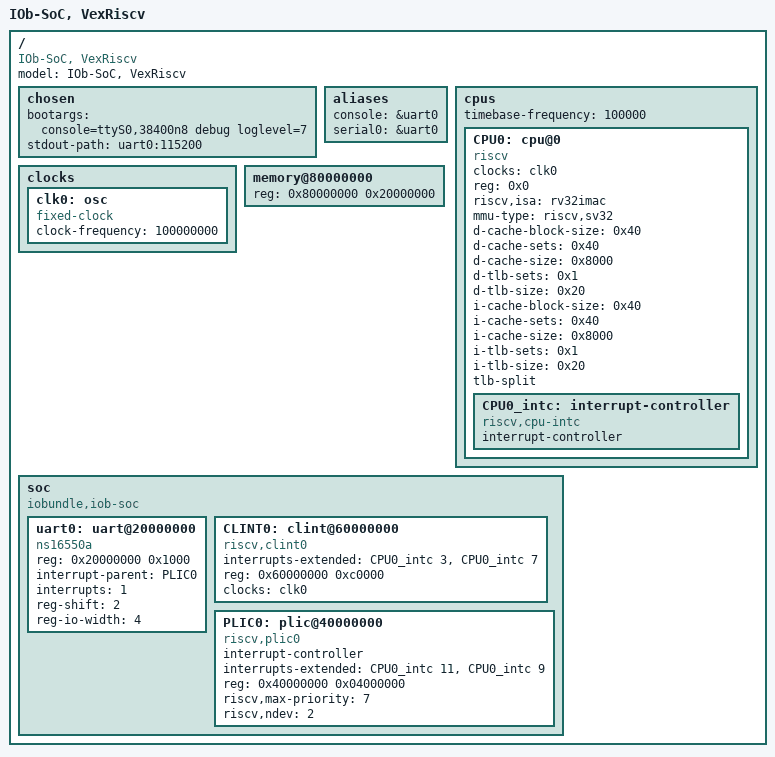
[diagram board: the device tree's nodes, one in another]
// SPDX-License-Identifier: (GPL-2.0 OR MIT)
/* Copyright (c) 2023 Pedro Antunes <pedronmantunes@gmail.com> */

/dts-v1/;

/ {
	#address-cells = <1>;
	#size-cells = <1>;
	model = "IOb-SoC, VexRiscv";
	compatible = "IOb-SoC, VexRiscv";

	chosen {
		bootargs = "console=ttyS0,38400n8 debug loglevel=7";
		stdout-path = "uart0:115200";
	};

	aliases {
		console = &uart0;
		serial0 = &uart0;
	};

	cpus {
		#address-cells = <0x1>;
		#size-cells = <0x0>;
		timebase-frequency = <100000>;
		CPU0: cpu@0 {
			clocks = <&clk0>;
			device_type = "cpu";
			reg = <0x0>;
			status = "okay";
			compatible = "riscv";
			riscv,isa = "rv32imac";
			mmu-type = "riscv,sv32";
			d-cache-block-size = <0x40>;
			d-cache-sets = <0x40>;
			d-cache-size = <0x8000>;
			d-tlb-sets = <0x1>;
			d-tlb-size = <0x20>;
			i-cache-block-size = <0x40>;
			i-cache-sets = <0x40>;
			i-cache-size = <0x8000>;
			i-tlb-sets = <0x1>;
			i-tlb-size = <0x20>;
			tlb-split;
			CPU0_intc: interrupt-controller {
				#interrupt-cells = <1>;
				interrupt-controller;
				compatible = "riscv,cpu-intc";
			};
		};
	};

	clocks {
		clk0: osc {
			compatible = "fixed-clock";
			#clock-cells = <0>;
			clock-frequency = <100000000>;
		};
	};

	memory@80000000 {
		device_type = "memory";
		reg = <0x80000000 0x20000000>;
	};

	soc {
		#address-cells = <1>;
		#size-cells = <1>;
		compatible = "iobundle,iob-soc", "simple-bus";
		ranges;

		uart0: uart@20000000 {
			compatible = "ns16550a";
			reg = <0x20000000 0x1000>;
			interrupt-parent = < &PLIC0 >;
			interrupts = <1>;
			reg-shift = <2>; // regs are spaced on 32 bit boundary
			reg-io-width = <4>; // only 32-bit access are supported
		};

		CLINT0: clint@60000000 {
			#interrupt-cells = <2>;
			compatible = "riscv,clint0";
			interrupts-extended = < &CPU0_intc 3
									&CPU0_intc 7 >;
			reg = <0x60000000 0xc0000>;
			reg-names = "control";
			clocks = <&clk0>;
		};

		PLIC0: plic@40000000 {
			#interrupt-cells = <1>;
			compatible = "riscv,plic0";
			interrupt-controller;
			interrupts-extended = < &CPU0_intc 11
									&CPU0_intc 9 >;
			reg = <0x40000000 0x04000000>;
			riscv,max-priority = <7>;
			riscv,ndev = <2>;
		};
	};
};
